# ATSAML21J18BU device description
Architecture: CORTEX-M0PLUS; Family: SAML; Series: SAML21
Registers are 32-bit, read-write, reset 0x0 unless marked. A register's access mark holds for its fields unless they carry their own. Offsets are from the block's base; [hi:lo] are bit positions; 'fields as' and 'values as' point back to an identical list.

## OTP5_FUSES — Non-Volatile Fuses
Instances: OTP5_FUSES 0x00806020 in fuses
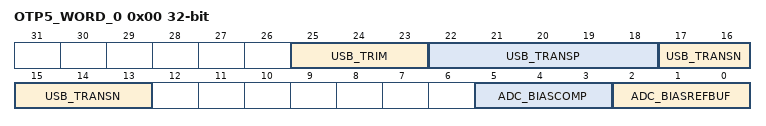
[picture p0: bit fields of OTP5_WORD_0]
0x00 OTP5_WORD_0 ro reset not defined — OTP5 Page Word 0
  [25:23] USB_TRIM — USB pad Trim calibration
  [22:18] USB_TRANSP — USB pad Transp calibration
  [17:13] USB_TRANSN — USB pad Transn calibration
  [5:3] ADC_BIASCOMP — ADC Comparator Scaling
  [2:0] ADC_BIASREFBUF — ADC Bias Reference Buffer Scaling

## TEMP_LOG_FUSES — Non-Volatile Fuses
Instances: TEMP_LOG_FUSES 0x00806030 in fuses
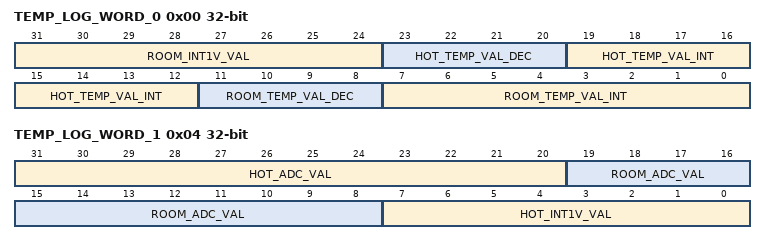
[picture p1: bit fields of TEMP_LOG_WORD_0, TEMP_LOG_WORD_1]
0x00 TEMP_LOG_WORD_0 ro reset not defined — TEMP_LOG Page Word 0
  [31:24] ROOM_INT1V_VAL — 2's complement of the internal 1V reference drift at room temperature (versus a 1.0 centered value)
  [23:20] HOT_TEMP_VAL_DEC — Decimal part of hot temperature
  [19:12] HOT_TEMP_VAL_INT — Integer part of hot temperature in oC
  [11:8] ROOM_TEMP_VAL_DEC — Decimal part of room temperature
  [7:0] ROOM_TEMP_VAL_INT — Integer part of room temperature in oC
0x04 TEMP_LOG_WORD_1 ro reset not defined — TEMP_LOG Page Word 1
  [31:20] HOT_ADC_VAL — 12-bit ADC conversion at hot temperature
  [19:8] ROOM_ADC_VAL — 12-bit ADC conversion at room temperature
  [7:0] HOT_INT1V_VAL — 2's complement of the internal 1V reference drift at hot temperature (versus a 1.0 centered value)

## USER_FUSES — Non-Volatile Fuses
Instances: USER_FUSES 0x00804000 in fuses
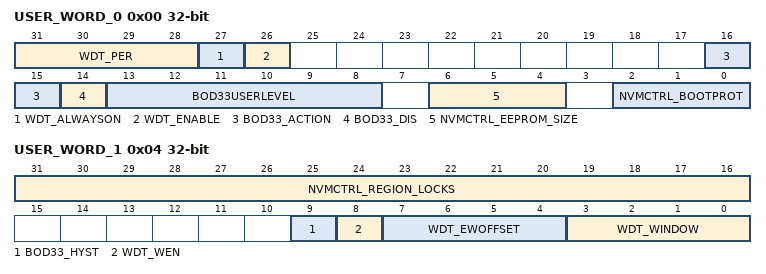
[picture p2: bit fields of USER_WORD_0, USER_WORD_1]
0x00 USER_WORD_0 reset not defined — USER Page Word 0
  [31:28] WDT_PER — WDT Period
    0=CYC8 (8 clock cycles); 1=CYC16 (16 clock cycles); 2=CYC32 (32 clock cycles); 3=CYC64 (64 clock cycles); 4=CYC128 (128 clock cycles); 5=CYC256 (256 clock cycles); 6=CYC512 (512 clock cycles); 7=CYC1024 (1024 clock cycles); 8=CYC2048 (2048 clock cycles); 9=CYC4096 (4096 clock cycles); 10=CYC8192 (8192 clock cycles); 11=CYC16384 (16384 clock cycles)
  [27] WDT_ALWAYSON
  [26] WDT_ENABLE
  [16:15] BOD33_ACTION
    0=NONE (No action); 1=RESET (The BOD33 generates a reset); 2=INT (The BOD33 generates an interrupt); 3=BKUP (The BOD33 puts the device in backup sleep mode)
  [14] BOD33_DIS — BOD33 Disable
  [13:8] BOD33USERLEVEL
  [6:4] NVMCTRL_EEPROM_SIZE — EEPROM Size
    7=SIZE_0BYTES (0 Bytes); 6=SIZE_256BYTES (256 Bytes); 5=SIZE_512BYTES (512 Bytes); 4=SIZE_1024BYTES (1024 Bytes); 3=SIZE_2048BYTES (2048 Bytes); 2=SIZE_4096BYTES (4096 Bytes); 1=SIZE_8192BYTES (8192 Bytes); 0=SIZE_16384BYTES (16384 Bytes)
  [2:0] NVMCTRL_BOOTPROT — Bootloader Size
    7=SIZE_0BYTES (0 Bytes); 6=SIZE_512BYTES (512 Bytes); 5=SIZE_1024BYTES (1024 Bytes); 4=SIZE_2048BYTES (2048 Bytes); 3=SIZE_4096BYTES (4096 Bytes); 2=SIZE_8192BYTES (8192 Bytes); 1=SIZE_16384BYTES (16384 Bytes); 0=SIZE_32768BYTES (32768 Bytes)
0x04 USER_WORD_1 reset not defined — USER Page Word 1
  [31:16] NVMCTRL_REGION_LOCKS — NVM Region Locks
  [9] BOD33_HYST — BOD33 Hysteresis
  [8] WDT_WEN — WDT Window Mode Enable
  [7:4] WDT_EWOFFSET — WDT Early Warning Offset
    values as USER_WORD_0.WDT_PER
  [3:0] WDT_WINDOW
    values as USER_WORD_0.WDT_PER

## OPAMP — Operational Amplifier
Instances: OPAMP 0x43001800
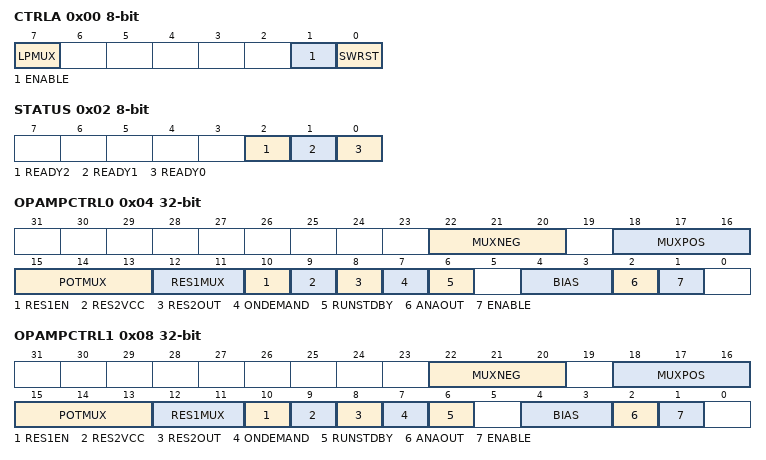
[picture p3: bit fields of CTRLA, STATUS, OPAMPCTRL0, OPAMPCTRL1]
0x00 CTRLA 8-bit — Control A
  [7] LPMUX — Low-Power Mux
  [1] ENABLE
  [0] SWRST — Software Reset
0x02 STATUS 8-bit ro
  [2] READY2 — OPAMP 2 Ready
  [1] READY1 — OPAMP 1 Ready
  [0] READY0 — OPAMP 0 Ready
0x04 OPAMPCTRL0 — OPAMP0 Control
  [22:20] MUXNEG — Negative Input Mux Selection
    0=OA0NEG (Negative I/O pin); 1=OA0TAP (Resistor ladder 0 taps); 2=OA0OUT (OPAMP0 output); 3=DAC (DAC output)
  [18:16] MUXPOS — Positive Input Mux Selection
    0=OA0POS (Positive I/O pin); 1=OA0TAP (Resistor ladder 0 taps); 2=DAC (DAC output); 3=GND (Ground)
  [15:13] POTMUX — Potentiometer Selection
    0=14R_2R (R1 = 14R, R2 = 2R); 1=12R_4R (R1 = 12R, R2 = 4R); 2=8R_8R (R1 = 8R, R2 = 8R); 3=6R_10R (R1 = 6R, R2 = 10R); 4=4R_12R (R1 = 4R, R2 = 12R); 5=3R_13R (R1 = 3R, R2 = 13R); 6=2R_14R (R1 = 2R, R2 = 14R); 7=R_15R (R1 = 1R, R2 = 15R)
  [12:11] RES1MUX — Resistor 1 Mux
    0=OAxPOS (Positive inout of OPAMPx); 1=OAxNEG (Negative input of OPAMPx); 2=DAC (DAC output); 3=GND (Ground)
  [10] RES1EN — Resistor 1 Enable
  [9] RES2VCC — Resistor ladder To VCC
  [8] RES2OUT — Resistor ladder To Output
  [7] ONDEMAND — On Demand Control
  [6] RUNSTDBY — Run in Standby
  [4:3] BIAS — Bias Selection
    0=MODE0 (Minimum current consumption, but the slowest mode); 1=MODE1 (Low current consumption, slow speed); 2=MODE2 (High current consumption, fast speed); 3=MODE3 (Maximum current consumption but the fastest mode)
  [2] ANAOUT — Analog Output
  [1] ENABLE — Operational Amplifier Enable
0x08 OPAMPCTRL1 — OPAMP1 Control
  [22:20] MUXNEG — Negative Input Mux Selection
    0=OA1NEG (Negative I/O pin); 1=OA1TAP (Resistor ladder 1 taps); 2=OA1OUT (OPAMP1 output); 3=DAC (DAC output)
  [18:16] MUXPOS — Positive Input Mux Selection
    0=OA1POS (Positive I/O pin); 1=OA1TAP (Resistor ladder 1 taps); 2=OA0OUT (OPAMP0 output); 3=GND (Ground)
  [15:13] POTMUX — Potentiometer Selection
    values as OPAMPCTRL0.POTMUX
  [12:11] RES1MUX — Resistor 1 Mux
    0=OAxPOS (Positive inout of OPAMPx); 1=OAxNEG (Negative input of OPAMPx); 2=OA0OUT (OPAMP0 output); 3=GND (Ground)
  [10] RES1EN — Resistor 1 Enable
  [9] RES2VCC — Resistor ladder To VCC
  [8] RES2OUT — Resistor ladder To Output
  [7] ONDEMAND — On Demand Control
  [6] RUNSTDBY — Run in Standby
  [4:3] BIAS — Bias Selection
    values as OPAMPCTRL0.BIAS
  [2] ANAOUT — Analog Output
  [1] ENABLE — Operational Amplifier Enable
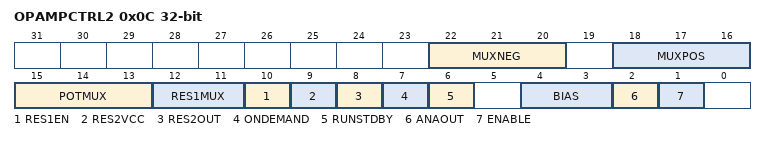
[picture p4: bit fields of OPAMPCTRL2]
0x0C OPAMPCTRL2 — OPAMP2 Control
  [22:20] MUXNEG — Negative Input Mux Selection
    0=OA2NEG (Negative I/O pin); 1=OA2TAP (Resistor ladder 2 taps); 2=OA2OUT (OPAMP2 output); 3=OA0NEG (Negative I/O pin OPA0); 4=OA1NEG (Negative I/O pin OPA1); 5=DAC (DAC output)
  [18:16] MUXPOS — Positive Input Mux Selection
    0=OA2POS (Positive I/O pin); 1=OA2TAP (Resistor ladder 2 taps); 2=OA1OUT (OPAMP1 output); 3=GND (Ground); 4=OA0POS (Positive I/O pin OPA0); 5=OA1POS (Positive I/O pin OPA1); 6=OA0TAP (Resistor ladder 0 taps)
  [15:13] POTMUX — Potentiometer Selection
    values as OPAMPCTRL0.POTMUX
  [12:11] RES1MUX — Resistor 1 Mux
    0=OAxPOS (Positive inout of OPAMPx); 1=OAxNEG (Negative input of OPAMPx); 2=OA1OUT (OPAMP1 output); 3=GND (Ground)
  [10] RES1EN — Resistor 1 Enable
  [9] RES2VCC — Resistor ladder To VCC
  [8] RES2OUT — Resistor ladder To Output
  [7] ONDEMAND — On Demand Control
  [6] RUNSTDBY — Run in Standby
  [4:3] BIAS — Bias Selection
    values as OPAMPCTRL0.BIAS
  [2] ANAOUT — Analog Output
  [1] ENABLE — Operational Amplifier Enable

## Notices in the file
Copyright (c) 2018 Microchip Technology Inc.
SPDX-License-Identifier: Apache-2.0
Licensed under the Apache License, Version 2.0 (the "License");
you may not use this file except in compliance with the License.
You may obtain a copy of the License at
http://www.apache.org/licenses/LICENSE-2.0
Unless required by applicable law or agreed to in writing, software
distributed under the License is distributed on an "AS IS" BASIS,
WITHOUT WARRANTIES OR CONDITIONS OF ANY KIND, either express or implied.
See the License for the specific language governing permissions and
limitations under the License.
